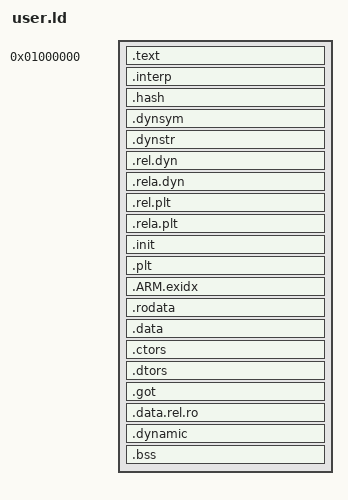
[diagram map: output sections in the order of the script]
/*
// Copyright 2016 The Fuchsia Authors
//
// Use of this source code is governed by a MIT-style
// license that can be found in the LICENSE file or at
// https://opensource.org/licenses/MIT
*/

OUTPUT_FORMAT("elf32-littlearm", "elf32-littlearm", "elf32-littlearm")
OUTPUT_ARCH(arm)

ENTRY(_start)
SECTIONS
{
    . = 0x01000000; /* base of user space */

    /* bump forward so the load offset and file offset are 1:1 */
    . += SIZEOF_HEADERS;

    /* text/read-only data */
    .text : {
        *(.crt)
        *(.text* .sram.text.glue_7* .gnu.linkonce.t.*)
    }

    .interp : { *(.interp) }
    .hash : { *(.hash) }
    .dynsym : { *(.dynsym) }
    .dynstr : { *(.dynstr) }
    .rel.dyn : {
        *(.rel.init)
        *(.rel.text .rel.text.* .rel.gnu.linkonce.t.*)
        *(.rel.fini)
        *(.rel.rodata .rel.rodata.* .rel.gnu.linkonce.r.*)
        *(.rel.data.rel.ro .rel.data.rel.ro.* .rel.gnu.linkonce.d.rel.ro.*)
        *(.rel.data .rel.data.* .rel.gnu.linkonce.d.*)
        *(.rel.tdata .rel.tdata.* .rel.gnu.linkonce.td.*)
        *(.rel.tbss .rel.tbss.* .rel.gnu.linkonce.tb.*)
        *(.rel.ctors)
        *(.rel.dtors)
        *(.rel.got)
        *(.rel.bss .rel.bss.* .rel.gnu.linkonce.b.*)
        PROVIDE_HIDDEN (__rel_iplt_start = .);
        *(.rel.iplt)
        PROVIDE_HIDDEN (__rel_iplt_end = .);
    }
    .rela.dyn : {
        *(.rela.init)
        *(.rela.text .rela.text.* .rela.gnu.linkonce.t.*)
        *(.rela.fini)
        *(.rela.rodata .rela.rodata.* .rela.gnu.linkonce.r.*)
        *(.rela.data .rela.data.* .rela.gnu.linkonce.d.*)
        *(.rela.tdata .rela.tdata.* .rela.gnu.linkonce.td.*)
        *(.rela.tbss .rela.tbss.* .rela.gnu.linkonce.tb.*)
        *(.rela.ctors)
        *(.rela.dtors)
        *(.rela.got)
        *(.rela.bss .rela.bss.* .rela.gnu.linkonce.b.*)
        PROVIDE_HIDDEN (__rela_iplt_start = .);
        *(.rela.iplt)
        PROVIDE_HIDDEN (__rela_iplt_end = .);
    }
    .rel.plt : { *(.rel.plt) }
    .rela.plt : { *(.rela.plt) }

    .init : { *(.init) } =0x9090
    .plt : { *(.plt) }

    /* .ARM.exidx is sorted, so has to go in its own output section.  */
    __exidx_start = .;
    .ARM.exidx : { *(.ARM.exidx* .gnu.linkonce.armexidx.*) }
    __exidx_end = .;

    .rodata : ALIGN(4) {
        __rodata_start = .;
        *(.rodata .rodata.* .gnu.linkonce.r.*)
        __rodata_end = .;
    }

    .data : ALIGN(4096) {
        __data_start = .;
        *(.data .data.* .gnu.linkonce.d.*)
    }

    .ctors : ALIGN(4) {
        __ctor_list = .;
        KEEP(*(.ctors .init_array))
        __ctor_end = .;
    }
    .dtors : ALIGN(4) {
        __dtor_list = .;
        KEEP(*(.dtors .fini_array))
        __dtor_end = .;
    }
    .got : { *(.got.plt) *(.got) }
    .data.rel.ro : { *(.data.rel.ro.local* .gnu.linkonce.d.rel.ro.local.*) *(.data.rel.ro .data.rel.ro.* .gnu.linkonce.d.rel.ro.*) }
    .dynamic : { *(.dynamic) }

    __data_end = .;

    /* unintialized data (in same segment as writable data) */
    .bss : ALIGN(4) {
        __bss_start = .;
        *(.bss .bss.*)
        *(.gnu.linkonce.b.*)
        *(COMMON)
        __bss_end = .;
    }

    _end = .;

    /* Strip unnecessary stuff */
    /DISCARD/ : { *(.comment .note) }
}
